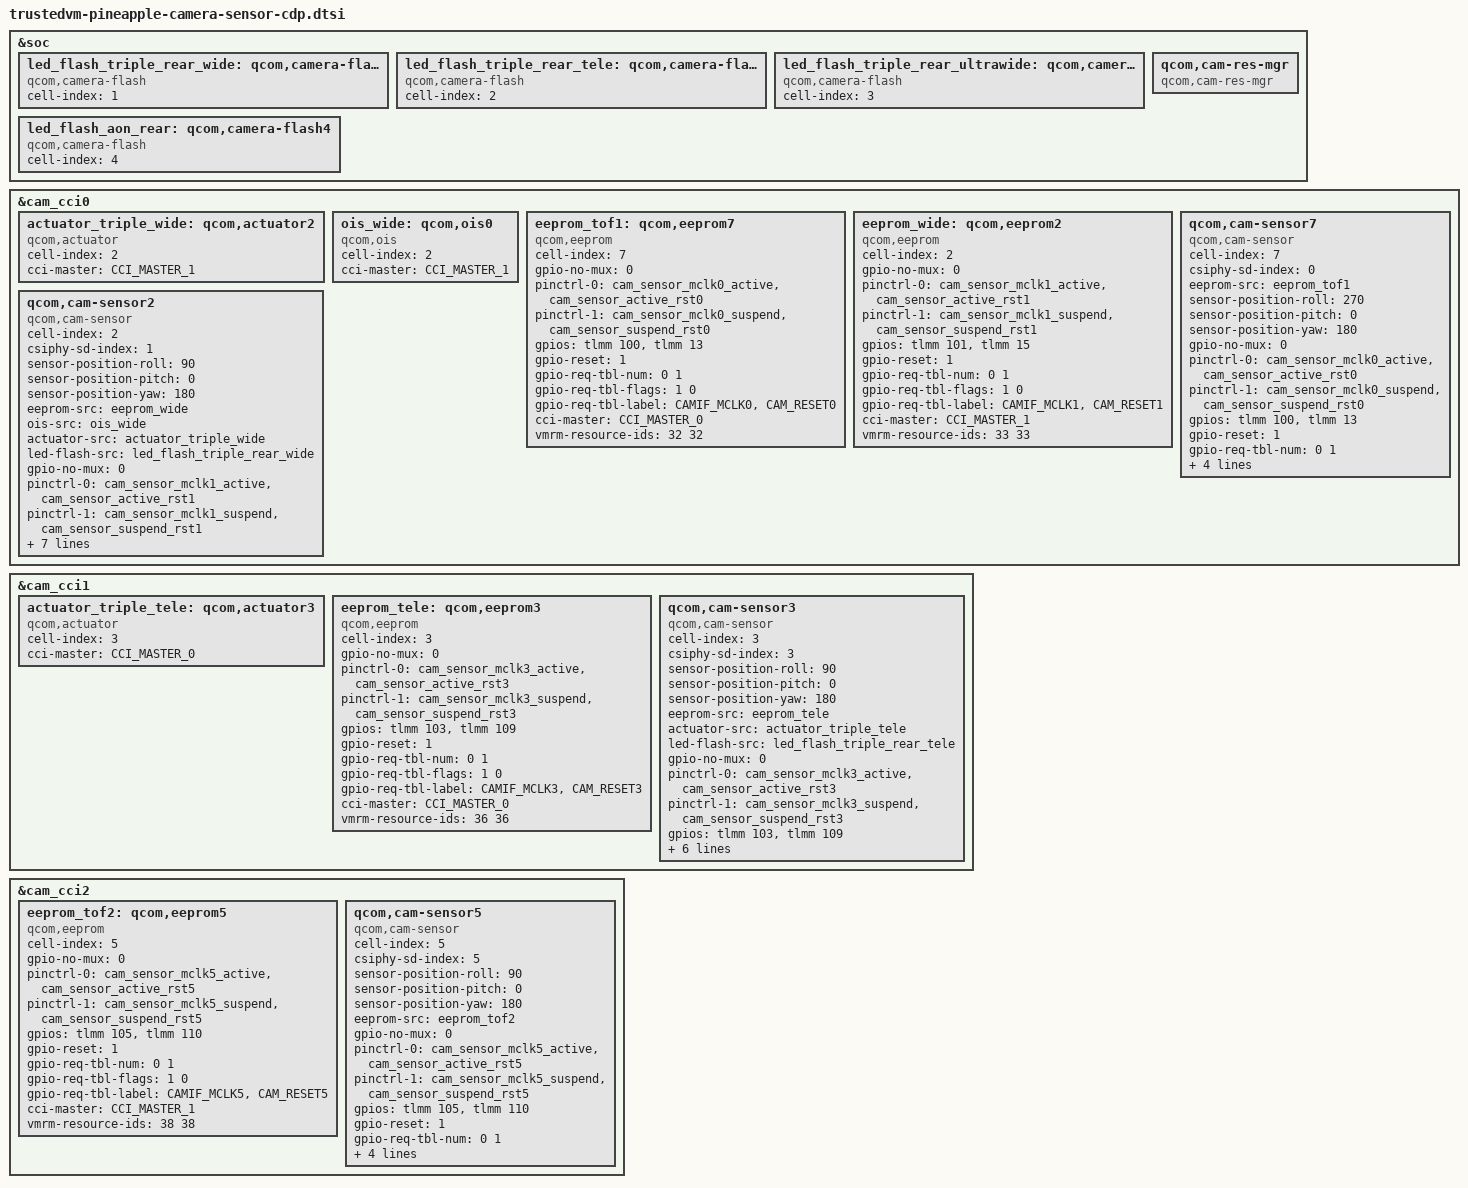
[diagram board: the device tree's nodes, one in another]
// SPDX-License-Identifier: BSD-3-Clause
/*
 * Copyright (c) 2023 Qualcomm Innovation Center, Inc. All rights reserved.
 */

&soc {
	led_flash_triple_rear_wide: qcom,camera-flash1 {
		cell-index = <1>;
		compatible = "qcom,camera-flash";
		status = "ok";
	};

	led_flash_triple_rear_tele: qcom,camera-flash2 {
		cell-index = <2>;
		compatible = "qcom,camera-flash";
		status = "ok";
	};

	led_flash_triple_rear_ultrawide: qcom,camera-flash3 {
		cell-index = <3>;
		compatible = "qcom,camera-flash";
		status = "ok";
	};

	led_flash_aon_rear: qcom,camera-flash4 {
		cell-index = <4>;
		compatible = "qcom,camera-flash";
		status = "ok";
	};

	qcom,cam-res-mgr {
		compatible = "qcom,cam-res-mgr";
		status = "ok";
	};
};

&cam_cci0 {

	actuator_triple_wide: qcom,actuator2 {
		cell-index = <2>;
		compatible = "qcom,actuator";
		cci-master = <CCI_MASTER_1>;
		status = "ok";
	};

	ois_wide: qcom,ois0 {
		cell-index = <2>;
		compatible = "qcom,ois";
		cci-master = <CCI_MASTER_1>;
		status = "ok";
	};

	eeprom_tof1: qcom,eeprom7 {
		cell-index = <7>;
		compatible = "qcom,eeprom";
		gpio-no-mux = <0>;
		pinctrl-names = "cam_default", "cam_suspend";
		pinctrl-0 = <&cam_sensor_mclk0_active
			&cam_sensor_active_rst0>;
		pinctrl-1 = <&cam_sensor_mclk0_suspend
			&cam_sensor_suspend_rst0>;
		gpios = <&tlmm 100 0>,
			<&tlmm 13 0>;
		gpio-reset = <1>;
		gpio-req-tbl-num = <0 1>;
		gpio-req-tbl-flags = <1 0>;
		gpio-req-tbl-label = "CAMIF_MCLK0",
			"CAM_RESET0";
		cci-master = <CCI_MASTER_0>;
		vmrm-resource-ids = <32 32>;
		status = "ok";
	};

	eeprom_wide: qcom,eeprom2 {
		cell-index = <2>;
		compatible = "qcom,eeprom";
		gpio-no-mux = <0>;
		pinctrl-names = "cam_default", "cam_suspend";
		pinctrl-0 = <&cam_sensor_mclk1_active
			&cam_sensor_active_rst1>;
		pinctrl-1 = <&cam_sensor_mclk1_suspend
			&cam_sensor_suspend_rst1>;
		gpios = <&tlmm 101 0>,
			<&tlmm 15 0>;
		gpio-reset = <1>;
		gpio-req-tbl-num = <0 1>;
		gpio-req-tbl-flags = <1 0>;
		gpio-req-tbl-label = "CAMIF_MCLK1",
			"CAM_RESET1";
		cci-master = <CCI_MASTER_1>;
		vmrm-resource-ids = <33 33>;
		status = "ok";
	};

	qcom,cam-sensor7 {
		cell-index = <7>;
		compatible = "qcom,cam-sensor";
		csiphy-sd-index = <0>;
		eeprom-src = <&eeprom_tof1>;
		sensor-position-roll = <270>;
		sensor-position-pitch = <0>;
		sensor-position-yaw = <180>;
		gpio-no-mux = <0>;
		pinctrl-names = "cam_default", "cam_suspend";
		pinctrl-0 = <&cam_sensor_mclk0_active
			&cam_sensor_active_rst0>;
		pinctrl-1 = <&cam_sensor_mclk0_suspend
			&cam_sensor_suspend_rst0>;
		gpios = <&tlmm 100 0>,
			<&tlmm 13 0>;
		gpio-reset = <1>;
		gpio-req-tbl-num = <0 1>;
		gpio-req-tbl-flags = <1 0>;
		gpio-req-tbl-label = "CAMIF_MCLK0",
			"CAM_RESET0";
		cci-master = <0>;
		vmrm-resource-ids = <34 34>;
		status = "ok";
	};

	qcom,cam-sensor2 {
		cell-index = <2>;
		compatible = "qcom,cam-sensor";
		csiphy-sd-index = <1>;
		sensor-position-roll = <90>;
		sensor-position-pitch = <0>;
		sensor-position-yaw = <180>;
		eeprom-src = <&eeprom_wide>;
		ois-src = <&ois_wide>;
		actuator-src = <&actuator_triple_wide>;
		led-flash-src = <&led_flash_triple_rear_wide>;
		gpio-no-mux = <0>;
		pinctrl-names = "cam_default", "cam_suspend";
		pinctrl-0 = <&cam_sensor_mclk1_active
			&cam_sensor_active_rst1>;
		pinctrl-1 = <&cam_sensor_mclk1_suspend
			&cam_sensor_suspend_rst1>;
		gpios = <&tlmm 101 0>,
			<&tlmm 15 0>;
		gpio-reset = <1>;
		gpio-req-tbl-num = <0 1>;
		gpio-req-tbl-flags = <1 0>;
		gpio-req-tbl-label = "CAMIF_MCLK1",
			"CAM_RESET1";
		cci-master = <CCI_MASTER_1>;
		vmrm-resource-ids = <35 35>;
		status = "ok";
	};

};

&cam_cci1 {
	actuator_triple_tele: qcom,actuator3{
		cell-index = <3>;
		compatible = "qcom,actuator";
		cci-master = <CCI_MASTER_0>;
		status = "ok";
	};

	eeprom_tele: qcom,eeprom3 {
		cell-index = <3>;
		compatible = "qcom,eeprom";
		gpio-no-mux = <0>;
		pinctrl-names = "cam_default", "cam_suspend";
		pinctrl-0 = <&cam_sensor_mclk3_active
			&cam_sensor_active_rst3>;
		pinctrl-1 = <&cam_sensor_mclk3_suspend
			&cam_sensor_suspend_rst3>;
		gpios = <&tlmm 103 0>,
			<&tlmm 109 0>;
		gpio-reset = <1>;
		gpio-req-tbl-num = <0 1>;
		gpio-req-tbl-flags = <1 0>;
		gpio-req-tbl-label = "CAMIF_MCLK3",
			"CAM_RESET3";
		cci-master = <CCI_MASTER_0>;
		vmrm-resource-ids = <36 36>;
		status = "ok";
	};

	qcom,cam-sensor3 {
		cell-index = <3>;
		compatible = "qcom,cam-sensor";
		csiphy-sd-index = <3>;
		sensor-position-roll = <90>;
		sensor-position-pitch = <0>;
		sensor-position-yaw = <180>;
		eeprom-src = <&eeprom_tele>;
		actuator-src = <&actuator_triple_tele>;
		led-flash-src = <&led_flash_triple_rear_tele>;
		gpio-no-mux = <0>;
		pinctrl-names = "cam_default", "cam_suspend";
		pinctrl-0 = <&cam_sensor_mclk3_active
			&cam_sensor_active_rst3>;
		pinctrl-1 = <&cam_sensor_mclk3_suspend
			&cam_sensor_suspend_rst3>;
		gpios = <&tlmm 103 0>,
			<&tlmm 109 0>;
		gpio-reset = <1>;
		gpio-req-tbl-num = <0 1>;
		gpio-req-tbl-flags = <1 0>;
		gpio-req-tbl-label = "CAMIF_MCLK3",
			"CAM_RESET3";
		cci-master = <CCI_MASTER_0>;
		vmrm-resource-ids = <37 37>;
		status = "ok";
	};

};

&cam_cci2 {
	eeprom_tof2: qcom,eeprom5 {
		cell-index = <5>;
		compatible = "qcom,eeprom";
		gpio-no-mux = <0>;
		pinctrl-names = "cam_default", "cam_suspend";
		pinctrl-0 = <&cam_sensor_mclk5_active
			&cam_sensor_active_rst5>;
		pinctrl-1 = <&cam_sensor_mclk5_suspend
			&cam_sensor_suspend_rst5>;
		gpios = <&tlmm 105 0>,
			<&tlmm 110 0>;
		gpio-reset = <1>;
		gpio-req-tbl-num = <0 1>;
		gpio-req-tbl-flags = <1 0>;
		gpio-req-tbl-label = "CAMIF_MCLK5",
			"CAM_RESET5";
		cci-master = <CCI_MASTER_1>;
		vmrm-resource-ids = <38 38>;
		status = "ok";
	};

	qcom,cam-sensor5 {
		cell-index = <5>;
		compatible = "qcom,cam-sensor";
		csiphy-sd-index = <5>;
		sensor-position-roll = <90>;
		sensor-position-pitch = <0>;
		sensor-position-yaw = <180>;
		eeprom-src = <&eeprom_tof2>;
		gpio-no-mux = <0>;
		pinctrl-names = "cam_default", "cam_suspend";
		pinctrl-0 = <&cam_sensor_mclk5_active
			&cam_sensor_active_rst5>;
		pinctrl-1 = <&cam_sensor_mclk5_suspend
			&cam_sensor_suspend_rst5>;
		gpios = <&tlmm 105 0>,
			<&tlmm 110 0>;
		gpio-reset = <1>;
		gpio-req-tbl-num = <0 1>;
		gpio-req-tbl-flags = <1 0>;
		gpio-req-tbl-label = "CAMIF_MCLK5",
			"CAM_RESET5";
		cci-master = <CCI_MASTER_1>;
		vmrm-resource-ids = <39 39>;
		status = "ok";
	};
};
